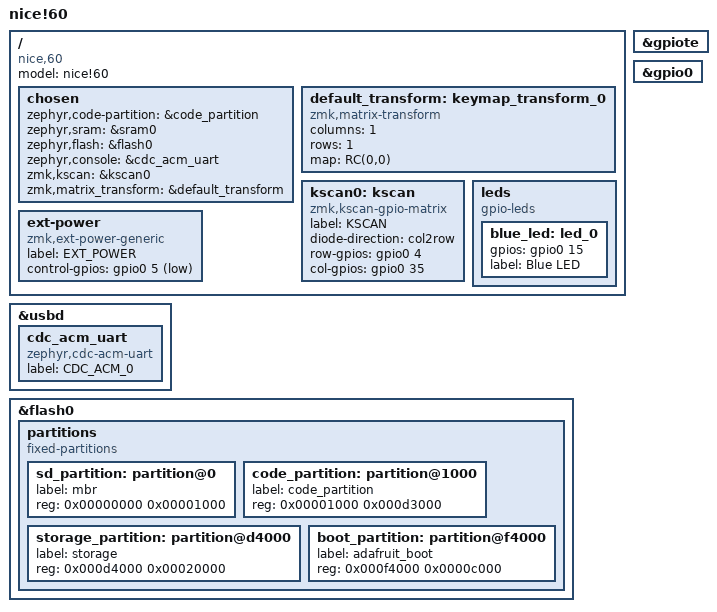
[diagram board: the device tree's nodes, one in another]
/*
 * Copyright (c) 2022 Karl Grasegger
 * SPDX-License-Identifier: MIT
 */

/dts-v1/;
#include <nordic/nrf52820_qdaa.dtsi>

#include <dt-bindings/zmk/matrix_transform.h>

/ {
	model = "nice!60";
	compatible = "nice,60";

	chosen {
		zephyr,code-partition = &code_partition;
		zephyr,sram = &sram0;
		zephyr,flash = &flash0;
		zephyr,console = &cdc_acm_uart;
		zmk,kscan = &kscan0;
		zmk,matrix_transform = &default_transform;
	};

	default_transform: keymap_transform_0 {
		compatible = "zmk,matrix-transform";
		columns = <1>;
		rows = <1>;
		map = <
RC(0,0)
		>;
	};

	kscan0: kscan {
		compatible = "zmk,kscan-gpio-matrix";
		label = "KSCAN";

		diode-direction = "col2row";
		row-gpios
			= <&gpio0 4 (GPIO_ACTIVE_HIGH | GPIO_PULL_DOWN)>
			;
		col-gpios
			= <&gpio0 35 GPIO_ACTIVE_HIGH>
			;
	};

	leds {
		compatible = "gpio-leds";
		blue_led: led_0 {
			gpios = <&gpio0 15 GPIO_ACTIVE_HIGH>;
			label = "Blue LED";
		};
	};

	ext-power {
		compatible = "zmk,ext-power-generic";
		label = "EXT_POWER";
		control-gpios = <&gpio0 5 GPIO_ACTIVE_LOW>;
	};
};

&gpiote {
	status = "okay";
};

&gpio0 {
	status = "okay";
};

&usbd {
	status = "okay";
	cdc_acm_uart: cdc_acm_uart {
		compatible = "zephyr,cdc-acm-uart";
		label = "CDC_ACM_0";
	};
};

&flash0 {
	/*
	 * For more information, see:
	 * http://docs.zephyrproject.org/latest/devices/dts/flash_partitions.html
	 */
	partitions {
		compatible = "fixed-partitions";
		#address-cells = <1>;
		#size-cells = <1>;

		sd_partition: partition@0 {
			label = "mbr";
			reg = <0x00000000 0x00001000>;
		};

		code_partition: partition@1000 {
			label = "code_partition";
			reg = <0x00001000 0x000d3000>;
		};

		/*
		 * The flash starting at 0x000d4000 and ending at
		 * 0x000f3fff is reserved for use by the application.
		 */

		/*
		 * Storage partition will be used by FCB/LittleFS/NVS
		 * if enabled.
		 */
		storage_partition: partition@d4000 {
			label = "storage";
			reg = <0x000d4000 0x00020000>;
		};

		boot_partition: partition@f4000 {
			label = "adafruit_boot";
			reg = <0x000f4000 0x0000c000>;
		};
	};
};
